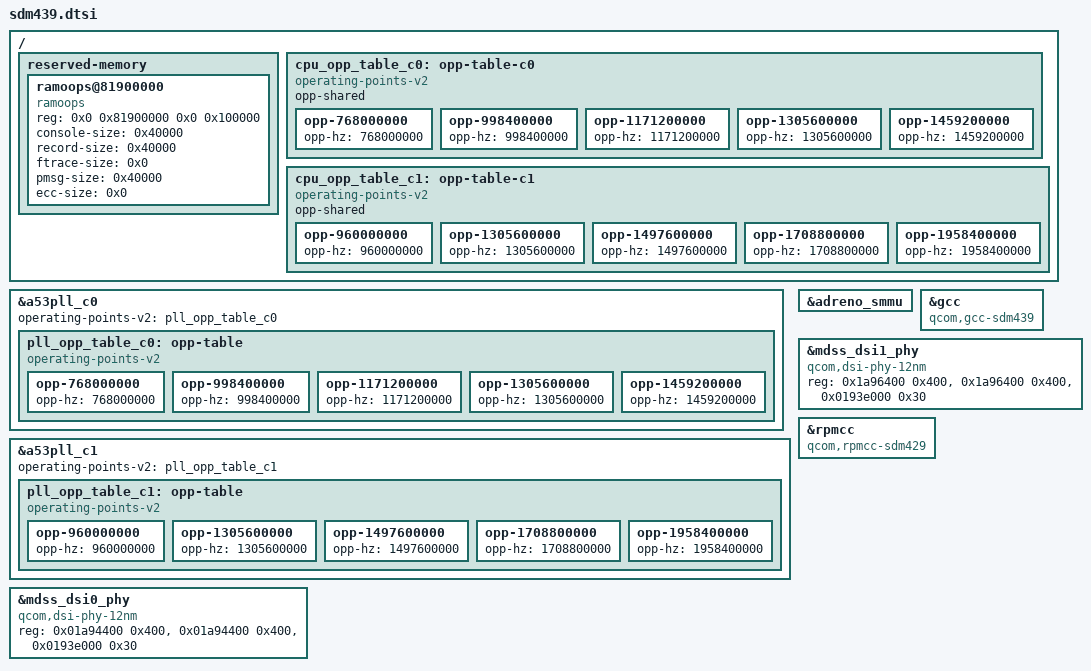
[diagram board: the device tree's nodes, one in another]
// SPDX-License-Identifier: BSD-3-Clause
/*
 * Copyright (c) 2025, Barnabas Czeman <barnabas.czeman@mainlining.org>
 */
#include "msm8937.dtsi"

/delete-node/ &cpu_opp_table_c0;
/delete-node/ &cpu_opp_table_c1;
/delete-node/ &pll_opp_table_c0;
/delete-node/ &pll_opp_table_c1;

/ {
	reserved-memory {
		ramoops@81900000 {
			compatible = "ramoops";
			reg = <0x0 0x81900000 0x0 0x100000>;
			console-size = <0x40000>;
			record-size = <0x40000>;
			ftrace-size = <0x0>;
			pmsg-size = <0x40000>;
			ecc-size = <0x0>;
		};
	};

	cpu_opp_table_c0: opp-table-c0 {
		compatible = "operating-points-v2";
		opp-shared;

		opp-768000000 {
			opp-hz = /bits/ 64 <768000000>;
		};

		opp-998400000 {
			opp-hz = /bits/ 64 <998400000>;
		};

		opp-1171200000 {
			opp-hz = /bits/ 64 <1171200000>;
		};

		opp-1305600000 {
			opp-hz = /bits/ 64 <1305600000>;
		};

		opp-1459200000 {
			opp-hz = /bits/ 64 <1459200000>;
		};
	};

	cpu_opp_table_c1: opp-table-c1 {
		compatible = "operating-points-v2";
		opp-shared;

		opp-960000000 {
			opp-hz = /bits/ 64 <960000000>;
		};

		opp-1305600000 {
			opp-hz = /bits/ 64 <1305600000>;
		};

		opp-1497600000 {
			opp-hz = /bits/ 64 <1497600000>;
		};

		opp-1708800000 {
			opp-hz = /bits/ 64 <1708800000>;
		};

		opp-1958400000 {
			opp-hz = /bits/ 64 <1958400000>;
		};
	};
};

&a53pll_c0 {
	operating-points-v2 = <&pll_opp_table_c0>;

	pll_opp_table_c0: opp-table {
		compatible = "operating-points-v2";

		opp-768000000 {
			opp-hz = /bits/ 64 <768000000>;
		};

		opp-998400000 {
			opp-hz = /bits/ 64 <998400000>;
		};

		opp-1171200000 {
			opp-hz = /bits/ 64 <1171200000>;
		};

		opp-1305600000 {
			opp-hz = /bits/ 64 <1305600000>;
		};

		opp-1459200000 {
			opp-hz = /bits/ 64 <1459200000>;
		};
	};
};

&a53pll_c1 {
	operating-points-v2 = <&pll_opp_table_c1>;

	pll_opp_table_c1: opp-table {
		compatible = "operating-points-v2";

		opp-960000000 {
			opp-hz = /bits/ 64 <960000000>;
		};

		opp-1305600000 {
			opp-hz = /bits/ 64 <1305600000>;
		};

		opp-1497600000 {
			opp-hz = /bits/ 64 <1497600000>;
		};

		opp-1708800000 {
			opp-hz = /bits/ 64 <1708800000>;
		};

		opp-1958400000 {
			opp-hz = /bits/ 64 <1958400000>;
		};
	};
};

&adreno_smmu {
	status = "okay";
};

/* GPU enabled via olive.dts */

&gcc {
	compatible = "qcom,gcc-sdm439";
};

&mdss_dsi0_phy {
	compatible = "qcom,dsi-phy-12nm";

	reg = <0x01a94400 0x400>,
	      <0x01a94400 0x400>,
	      <0x0193e000 0x30>;

	reg-names = "dsi_pll",
		    "dsi_phy",
		    "dsi_phy_regulator";
};

&mdss_dsi1_phy {
	compatible = "qcom,dsi-phy-12nm";

	reg = <0x1a96400 0x400>,
	      <0x1a96400 0x400>,
	      <0x0193e000 0x30>;

	reg-names = "dsi_pll",
		    "dsi_phy",
		    "dsi_phy_regulator";
};

&rpmcc {
	compatible = "qcom,rpmcc-sdm429", "qcom,rpmcc";
};
